# STM32H7A3x register map
File version: 1.8
CPU: CM7 r0p1, little endian, MPU, FPU, 4 interrupt priority bits
Registers are 32-bit, read-write, reset 0x0 unless marked. A register's access mark holds for its fields unless they carry their own. Offsets are from the block's base; [hi:lo] are bit positions; {n}, {i} and the like mark numbered series.

## SYSCFG — System configuration controller
Base 0x58000400
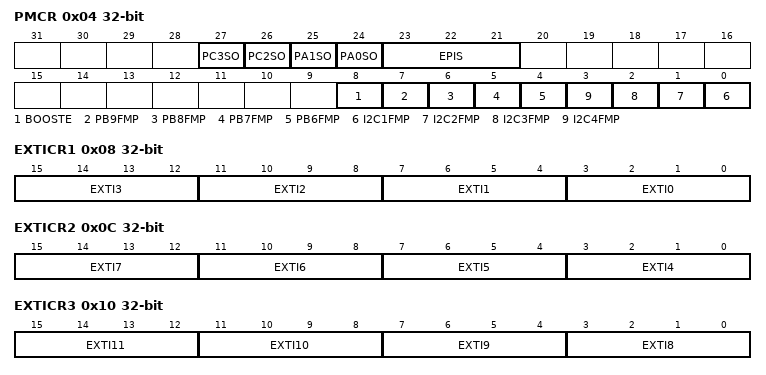
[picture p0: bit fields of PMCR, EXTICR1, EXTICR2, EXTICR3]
0x04 PMCR — peripheral mode configuration register
  [27] PC3SO — PC3 Switch Open
  [26] PC2SO — PC2 Switch Open
  [25] PA1SO — PA1 Switch Open
  [24] PA0SO — PA0 Switch Open
  [23:21] EPIS — Ethernet PHY Interface Selection
  [8] BOOSTE — Booster Enable
  [7] PB9FMP — PB(9) Fm+
  [6] PB8FMP — PB(8) Fast Mode Plus
  [5] PB7FMP — PB(7) Fast Mode Plus
  [4] PB6FMP — PB(6) Fm+
  [n-1] I2C{n}FMP (n=1..4) — I2C{n} Fm+
0x08 EXTICR1 — external interrupt configuration register 1
  [4n+3:4n] EXTI{n} (n=0..3) — EXTI x configuration (x = 0 to 3)
0x0C EXTICR2 — external interrupt configuration register 2
  [4n-13:4n-16] EXTI{n} (n=4..7) — EXTI x configuration (x = 4 to 7)
0x10 EXTICR3 — external interrupt configuration register 3
  [15:12] EXTI11 — EXTI x configuration (x = 8 to 11)
  [11:8] EXTI10
  [7:4] EXTI9 — EXTI x configuration (x = 8 to 11)
  [3:0] EXTI8 — EXTI x configuration (x = 8 to 11)
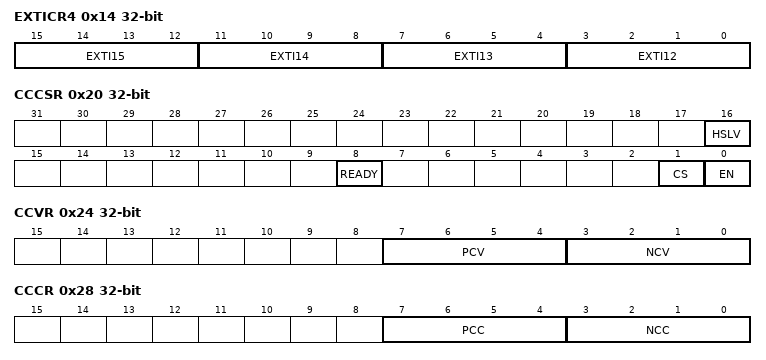
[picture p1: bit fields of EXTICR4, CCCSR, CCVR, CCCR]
0x14 EXTICR4 — external interrupt configuration register 4
  [4n-45:4n-48] EXTI{n} (n=12..15) — EXTI x configuration (x = 12 to 15)
0x20 CCCSR — compensation cell control/status register
  [16] HSLV — High-speed at low-voltage
  [8] READY — Compensation cell ready flag
  [1] CS — Code selection
  [0] EN — enable
0x24 CCVR ro — SYSCFG compensation cell value register
  [7:4] PCV — PMOS compensation value
  [3:0] NCV — NMOS compensation value
0x28 CCCR — SYSCFG compensation cell code register
  [7:4] PCC — PMOS compensation code
  [3:0] NCC — NMOS compensation code
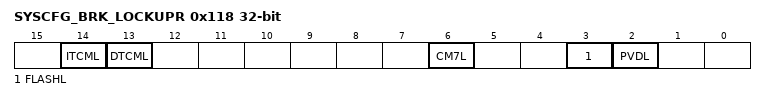
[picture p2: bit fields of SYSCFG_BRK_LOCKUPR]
0x118 SYSCFG_BRK_LOCKUPR — SYSCFG timer break lockup register
  [14] ITCML — ITCM double ECC error signal lock
  [13] DTCML — D1TCM or D0TCM double ECC error signal lock
  [6] CM7L — CortexÃƒÆ’Ã¢â‚¬Å¡Ãƒâ€šÃ‚Â®-M7 LOCKUP (HardFault) output enable bit
  [3] FLASHL — Flash double ECC error lock bit
  [2] PVDL — PVD lock enable bit.

## DELAY_Block_SDMMC1
Base 0x52008000
Same registers: DELAY_Block_SDMMC2 0x48022800, Delay_Block_OCTOSPI1 0x52006000, Delay_Block_OCTOSPI2 0x5200B000
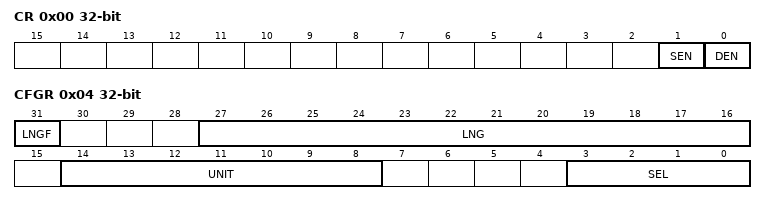
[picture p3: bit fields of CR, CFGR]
0x00 CR — DLYB control register
  [1] SEN — Sampler length enable bit
  [0] DEN — Delay block enable bit
0x04 CFGR — DLYB configuration register
  [31] LNGF — Length valid flag
  [27:16] LNG — Delay line length value
  [14:8] UNIT — Delay Defines the delay of a Unit delay cell
  [3:0] SEL — Select the phase for the Output clock

## DCMI — Digital camera interface
Base 0x48020000
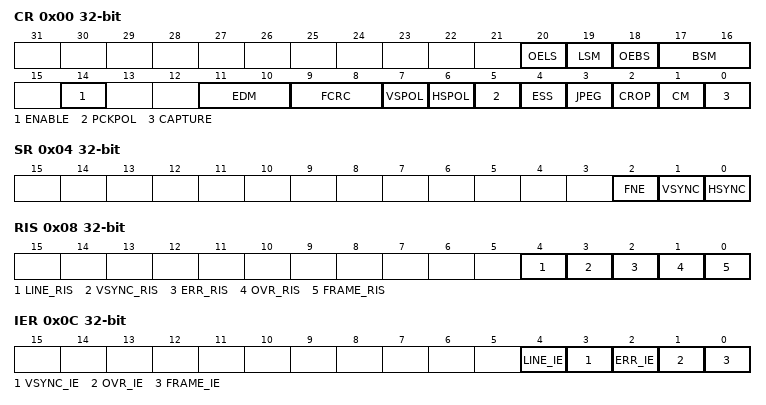
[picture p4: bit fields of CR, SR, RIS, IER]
0x00 CR — control register 1
  [20] OELS — Odd/Even Line Select (Line Select Start)
  [19] LSM — Line Select mode
  [18] OEBS — Odd/Even Byte Select (Byte Select Start)
  [17:16] BSM — Byte Select mode
  [14] ENABLE — DCMI enable
  [11:10] EDM — Extended data mode
  [9:8] FCRC — Frame capture rate control
  [7] VSPOL — Vertical synchronization polarity
  [6] HSPOL — Horizontal synchronization polarity
  [5] PCKPOL — Pixel clock polarity
  [4] ESS — Embedded synchronization select
  [3] JPEG — JPEG format
  [2] CROP — Crop feature
  [1] CM — Capture mode
  [0] CAPTURE — Capture enable
0x04 SR ro — status register
  [2] FNE — FIFO not empty
  [1] VSYNC
  [0] HSYNC
0x08 RIS ro — raw interrupt status register
  [4] LINE_RIS — Line raw interrupt status
  [3] VSYNC_RIS — VSYNC raw interrupt status
  [2] ERR_RIS — Synchronization error raw interrupt status
  [1] OVR_RIS — Overrun raw interrupt status
  [0] FRAME_RIS — Capture complete raw interrupt status
0x0C IER — interrupt enable register
  [4] LINE_IE — Line interrupt enable
  [3] VSYNC_IE — VSYNC interrupt enable
  [2] ERR_IE — Synchronization error interrupt enable
  [1] OVR_IE — Overrun interrupt enable
  [0] FRAME_IE — Capture complete interrupt enable
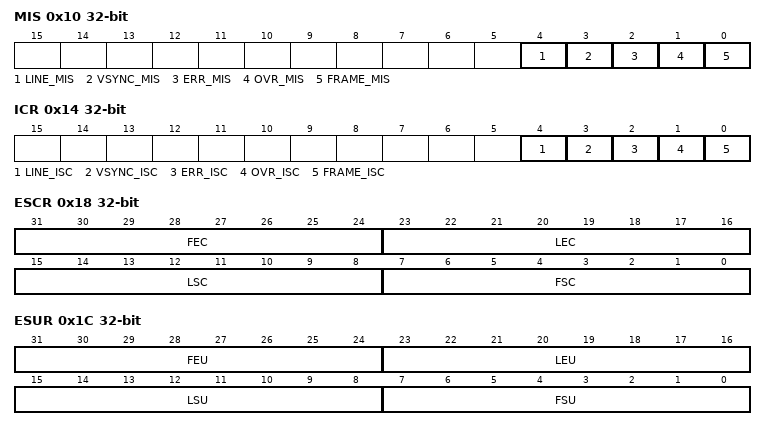
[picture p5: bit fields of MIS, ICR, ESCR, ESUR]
0x10 MIS ro — masked interrupt status register
  [4] LINE_MIS — Line masked interrupt status
  [3] VSYNC_MIS — VSYNC masked interrupt status
  [2] ERR_MIS — Synchronization error masked interrupt status
  [1] OVR_MIS — Overrun masked interrupt status
  [0] FRAME_MIS — Capture complete masked interrupt status
0x14 ICR wo — interrupt clear register
  [4] LINE_ISC — line interrupt status clear
  [3] VSYNC_ISC — Vertical synch interrupt status clear
  [2] ERR_ISC — Synchronization error interrupt status clear
  [1] OVR_ISC — Overrun interrupt status clear
  [0] FRAME_ISC — Capture complete interrupt status clear
0x18 ESCR — embedded synchronization code register
  [31:24] FEC — Frame end delimiter code
  [23:16] LEC — Line end delimiter code
  [15:8] LSC — Line start delimiter code
  [7:0] FSC — Frame start delimiter code
0x1C ESUR — embedded synchronization unmask register
  [31:24] FEU — Frame end delimiter unmask
  [23:16] LEU — Line end delimiter unmask
  [15:8] LSU — Line start delimiter unmask
  [7:0] FSU — Frame start delimiter unmask
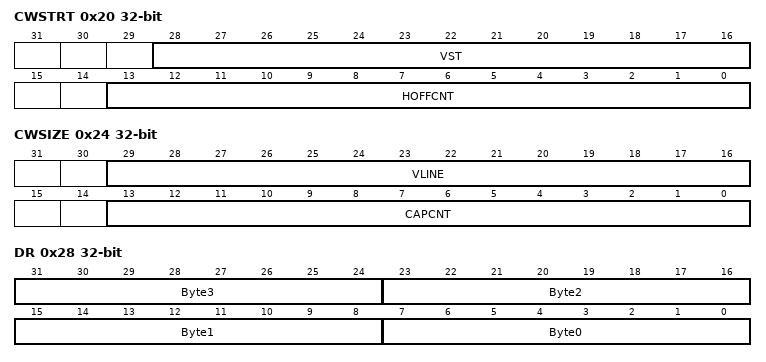
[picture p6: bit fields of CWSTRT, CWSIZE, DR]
0x20 CWSTRT — crop window start
  [28:16] VST — Vertical start line count
  [13:0] HOFFCNT — Horizontal offset count
0x24 CWSIZE — crop window size
  [29:16] VLINE — Vertical line count
  [13:0] CAPCNT — Capture count
0x28 DR ro — data register
  [8n+7:8n] Byte{n} (n=0..3) — Data byte {n}
